VERSION ""

NS_ :

BS_:

BU_: microSDM_102 PDM30 MS6 IM_GCM IZZE_RL IZZE_FL IZZE_RR IZZE_FR IMU WL_IZZE_RIGHT WL_IZZE_LEFT IZZE_BRK_IR IM_PDM IM_Wheel S350

BO_ 3221225472 VECTOR__INDEPENDENT_SIG_MSG: 0 Vector__XXX
 SG_ LT2_Lambda_2 : 0|16@1+ (0.001,0) [0|0] "L" Vector__XXX
 SG_ LT2_Row_Count : 0|8@1+ (1,0) [0|0] "" Vector__XXX
 SG_ LT2_Lambda_1 : 0|16@1+ (0.001,0) [0|0] "L" Vector__XXX
 SG_ LT2_Row_Count : 0|8@1+ (1,0) [0|0] "" Vector__XXX
 SG_ LT2_Lambda_2 : 0|16@1+ (0.001,0) [0|0] "L" Vector__XXX
 SG_ LT2_Row_Count : 0|8@1+ (1,0) [0|0] "" Vector__XXX
 SG_ LT2_Lambda_1 : 0|16@1+ (0.001,0) [0|0] "L" Vector__XXX
 SG_ LT2_Row_Count : 0|8@1+ (1,0) [0|0] "" Vector__XXX

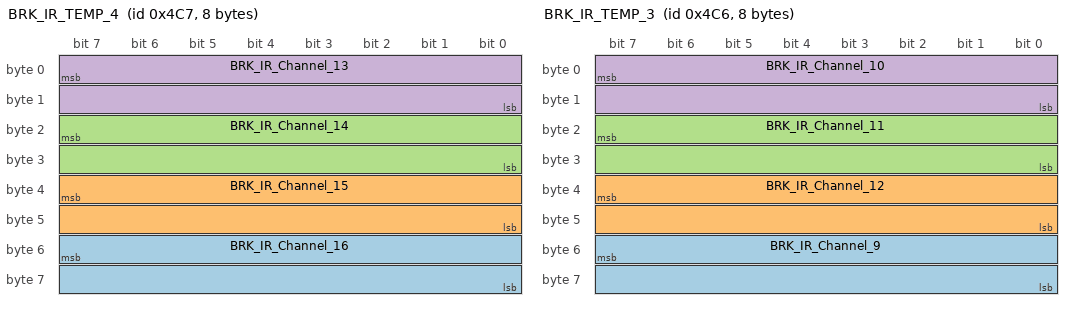
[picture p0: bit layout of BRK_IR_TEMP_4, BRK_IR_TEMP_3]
BO_ 1223 BRK_IR_TEMP_4: 8 IZZE_BRK_IR
 SG_ BRK_IR_Channel_16 : 55|16@0+ (0.1,-100) [0|65535] "C" Vector__XXX
 SG_ BRK_IR_Channel_15 : 39|16@0+ (0.1,-100) [0|65535] "C" Vector__XXX
 SG_ BRK_IR_Channel_14 : 23|16@0+ (0.1,-100) [0|65535] "C" Vector__XXX
 SG_ BRK_IR_Channel_13 : 7|16@0+ (0.1,-100) [0|65535] "C" Vector__XXX

BO_ 1222 BRK_IR_TEMP_3: 8 IZZE_BRK_IR
 SG_ BRK_IR_Channel_9 : 55|16@0+ (0.1,-100) [0|65535] "C" Vector__XXX
 SG_ BRK_IR_Channel_12 : 39|16@0+ (0.1,-100) [0|65535] "C" Vector__XXX
 SG_ BRK_IR_Channel_11 : 23|16@0+ (0.1,-100) [0|65535] "C" Vector__XXX
 SG_ BRK_IR_Channel_10 : 7|16@0+ (0.1,-100) [0|65535] "C" Vector__XXX

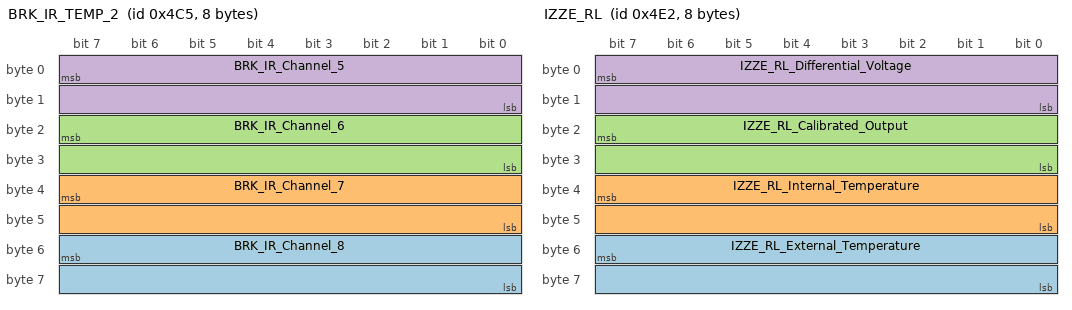
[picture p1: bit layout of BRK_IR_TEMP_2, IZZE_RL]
BO_ 1221 BRK_IR_TEMP_2: 8 IZZE_BRK_IR
 SG_ BRK_IR_Channel_8 : 55|16@0+ (0.1,-100) [0|65535] "C" Vector__XXX
 SG_ BRK_IR_Channel_7 : 39|16@0+ (0.1,-100) [0|65535] "C" Vector__XXX
 SG_ BRK_IR_Channel_6 : 23|16@0+ (0.1,-100) [0|65535] "C" Vector__XXX
 SG_ BRK_IR_Channel_5 : 7|16@0+ (0.1,-100) [0|65535] "C" Vector__XXX

BO_ 1552 IM_GCM_MS6_Control: 8 IM_GCM
 SG_ GCM_Upshift_Bosch : 1|1@1+ (1,0) [0|0] "" Vector__XXX
 SG_ GCM_Downshift_Bosch : 0|1@1+ (1,0) [0|0] "" Vector__XXX

BO_ 1250 IZZE_RL: 8 IZZE_RL
 SG_ IZZE_RL_External_Temperature : 55|16@0- (0.1,0) [0|0] "C" Vector__XXX
 SG_ IZZE_RL_Internal_Temperature : 39|16@0- (0.1,0) [0|0] "C" Vector__XXX
 SG_ IZZE_RL_Calibrated_Output : 23|16@0- (0.1,0) [0|0] "F" Vector__XXX
 SG_ IZZE_RL_Differential_Voltage : 7|16@0- (1,0) [0|0] "µV" Vector__XXX

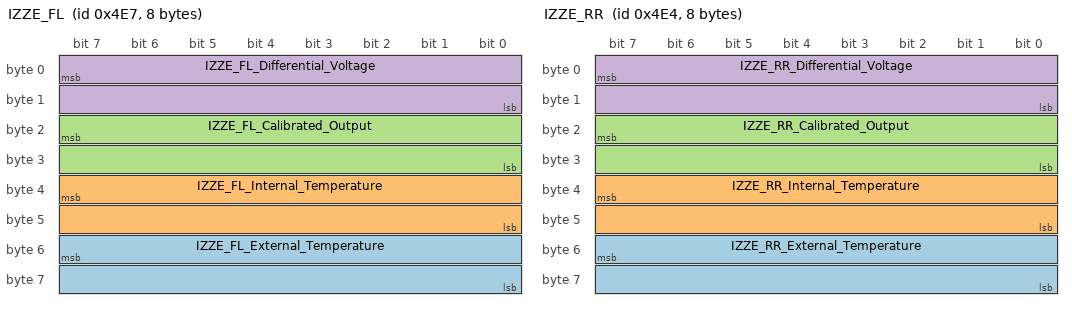
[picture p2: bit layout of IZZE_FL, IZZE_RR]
BO_ 1255 IZZE_FL: 8 IZZE_FL
 SG_ IZZE_FL_External_Temperature : 55|16@0- (0.1,0) [0|0] "C" Vector__XXX
 SG_ IZZE_FL_Internal_Temperature : 39|16@0- (0.1,0) [0|0] "C" Vector__XXX
 SG_ IZZE_FL_Calibrated_Output : 23|16@0- (0.1,0) [0|0] "F" Vector__XXX
 SG_ IZZE_FL_Differential_Voltage : 7|16@0- (1,0) [0|0] "µV" Vector__XXX

BO_ 1252 IZZE_RR: 8 IZZE_RR
 SG_ IZZE_RR_External_Temperature : 55|16@0- (0.1,0) [0|0] "C" Vector__XXX
 SG_ IZZE_RR_Internal_Temperature : 39|16@0- (0.1,0) [0|0] "C" Vector__XXX
 SG_ IZZE_RR_Calibrated_Output : 23|16@0- (0.1,0) [0|0] "F" Vector__XXX
 SG_ IZZE_RR_Differential_Voltage : 7|16@0- (1,0) [0|0] "µV" Vector__XXX

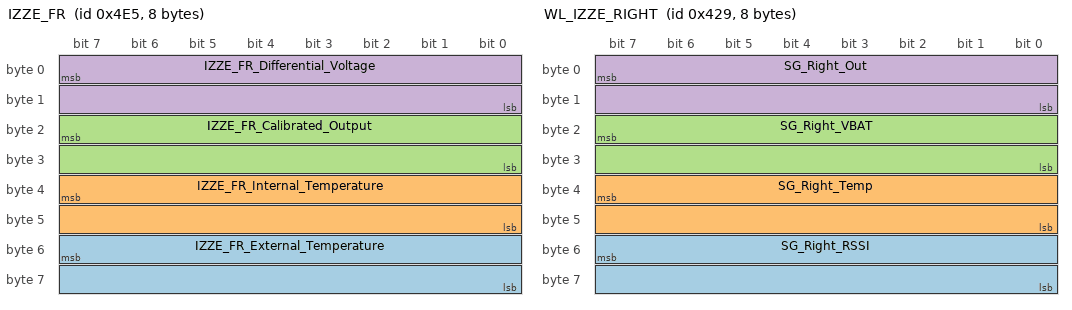
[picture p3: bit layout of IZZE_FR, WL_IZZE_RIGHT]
BO_ 1253 IZZE_FR: 8 IZZE_FR
 SG_ IZZE_FR_External_Temperature : 55|16@0- (0.1,0) [0|0] "C" Vector__XXX
 SG_ IZZE_FR_Internal_Temperature : 39|16@0- (0.1,0) [0|0] "C" Vector__XXX
 SG_ IZZE_FR_Calibrated_Output : 23|16@0- (0.1,0) [0|0] "F" Vector__XXX
 SG_ IZZE_FR_Differential_Voltage : 7|16@0- (1,0) [0|0] "µV" Vector__XXX

BO_ 380 IMU_2: 8 IMU
 SG_ IMU_Z_Accel : 32|16@1+ (0.0001274,-4.1746432) [0|0] "g" Vector__XXX

BO_ 1065 WL_IZZE_RIGHT: 8 WL_IZZE_RIGHT
 SG_ SG_Right_RSSI : 55|16@0- (1,0) [0|0] "dBm" Vector__XXX
 SG_ SG_Right_Temp : 39|16@0- (0.1,0) [0|0] "C" Vector__XXX
 SG_ SG_Right_VBAT : 23|16@0- (0.001,0) [0|0] "V" Vector__XXX
 SG_ SG_Right_Out : 7|16@0- (-1,0) [0|0] "uV" Vector__XXX

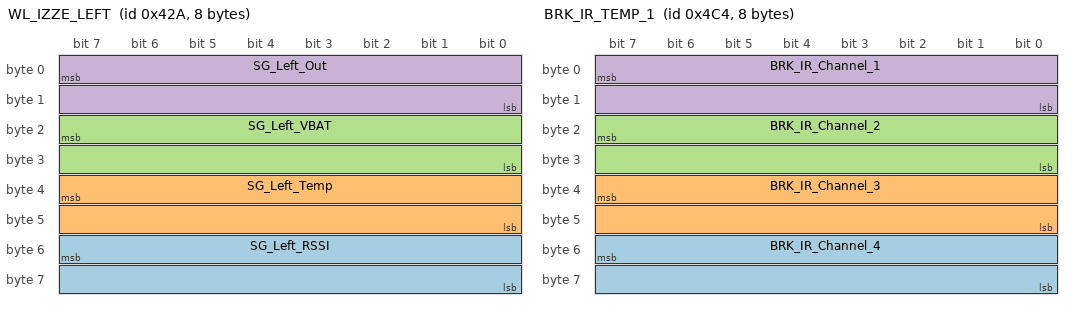
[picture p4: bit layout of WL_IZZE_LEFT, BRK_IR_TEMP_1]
BO_ 1066 WL_IZZE_LEFT: 8 WL_IZZE_LEFT
 SG_ SG_Left_RSSI : 55|16@0- (1,0) [0|0] "dBm" Vector__XXX
 SG_ SG_Left_Temp : 39|16@0- (0.1,0) [0|0] "C" Vector__XXX
 SG_ SG_Left_VBAT : 23|16@0- (0.001,0) [0|0] "V" Vector__XXX
 SG_ SG_Left_Out : 7|16@0- (1,0) [0|0] "uV" Vector__XXX

BO_ 1220 BRK_IR_TEMP_1: 8 IZZE_BRK_IR
 SG_ BRK_IR_Channel_4 : 55|16@0+ (0.1,-100) [0|65535] "C" Vector__XXX
 SG_ BRK_IR_Channel_3 : 39|16@0+ (0.1,-100) [0|65535] "C" Vector__XXX
 SG_ BRK_IR_Channel_2 : 23|16@0+ (0.1,-100) [0|65535] "C" Vector__XXX
 SG_ BRK_IR_Channel_1 : 7|16@0+ (0.1,-100) [0|65535] "C" Vector__XXX

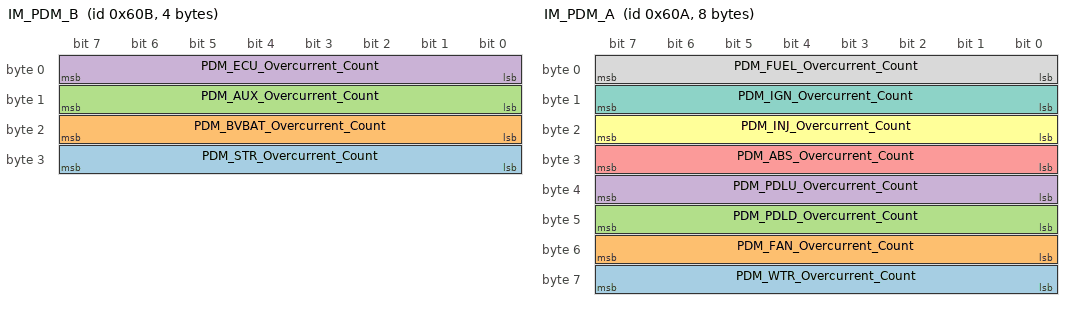
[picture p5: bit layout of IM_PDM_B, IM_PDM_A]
BO_ 1547 IM_PDM_B: 4 IM_PDM
 SG_ PDM_STR_Overcurrent_Count : 24|8@1+ (1,0) [0|0] "" Vector__XXX
 SG_ PDM_BVBAT_Overcurrent_Count : 16|8@1+ (1,0) [0|0] "" Vector__XXX
 SG_ PDM_AUX_Overcurrent_Count : 8|8@1+ (1,0) [0|0] "" Vector__XXX
 SG_ PDM_ECU_Overcurrent_Count : 0|8@1+ (1,0) [0|0] "" Vector__XXX

BO_ 1546 IM_PDM_A: 8 IM_PDM
 SG_ PDM_WTR_Overcurrent_Count : 56|8@1+ (1,0) [0|0] "" Vector__XXX
 SG_ PDM_FAN_Overcurrent_Count : 48|8@1+ (1,0) [0|0] "" Vector__XXX
 SG_ PDM_PDLD_Overcurrent_Count : 40|8@1+ (1,0) [0|0] "" Vector__XXX
 SG_ PDM_PDLU_Overcurrent_Count : 32|8@1+ (1,0) [0|0] "" Vector__XXX
 SG_ PDM_ABS_Overcurrent_Count : 24|8@1+ (1,0) [0|0] "" Vector__XXX
 SG_ PDM_INJ_Overcurrent_Count : 16|8@1+ (1,0) [0|0] "" Vector__XXX
 SG_ PDM_IGN_Overcurrent_Count : 8|8@1+ (1,0) [0|0] "" Vector__XXX
 SG_ PDM_FUEL_Overcurrent_Count : 0|8@1+ (1,0) [0|0] "" Vector__XXX

BO_ 376 IMU_1: 8 IMU
 SG_ IMU_X_Accel : 32|16@1+ (0.0001274,-4.1746432) [0|0] "g" Vector__XXX
 SG_ IMU_Roll_Rate : 0|16@1+ (0.005,-163.84) [0|0] "deg/s/s" Vector__XXX

BO_ 372 IMU_0: 8 IMU
 SG_ IMU_Y_Accel : 32|16@1+ (0.0001274,-4.1746432) [0|0] "g" Vector__XXX
 SG_ IMU_Yaw_Rate : 0|16@1+ (0.005,-163.84) [0|0] "deg/s" Vector__XXX

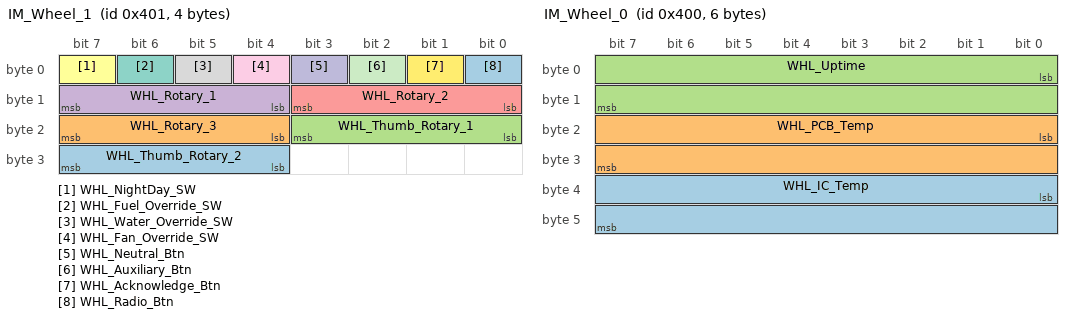
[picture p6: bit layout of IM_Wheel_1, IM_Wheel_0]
BO_ 1025 IM_Wheel_1: 4 IM_Wheel
 SG_ WHL_Thumb_Rotary_2 : 28|4@1+ (1,0) [0|0] "" Vector__XXX
 SG_ WHL_Rotary_3 : 20|4@1+ (1,0) [0|0] "" Vector__XXX
 SG_ WHL_Thumb_Rotary_1 : 16|4@1+ (1,0) [0|0] "" Vector__XXX
 SG_ WHL_Rotary_1 : 12|4@1+ (1,0) [0|0] "" Vector__XXX
 SG_ WHL_Rotary_2 : 8|4@1+ (1,0) [0|0] "" Vector__XXX
 SG_ WHL_NightDay_SW : 7|1@1+ (1,0) [0|0] "" Vector__XXX
 SG_ WHL_Fuel_Override_SW : 6|1@1+ (1,0) [0|0] "" Vector__XXX
 SG_ WHL_Water_Override_SW : 5|1@1+ (1,0) [0|0] "" Vector__XXX
 SG_ WHL_Fan_Override_SW : 4|1@1+ (1,0) [0|0] "" Vector__XXX
 SG_ WHL_Neutral_Btn : 3|1@1+ (1,0) [0|0] "" Vector__XXX
 SG_ WHL_Auxiliary_Btn : 2|1@1+ (1,0) [0|0] "" Vector__XXX
 SG_ WHL_Acknowledge_Btn : 1|1@1+ (1,0) [0|0] "" Vector__XXX
 SG_ WHL_Radio_Btn : 0|1@1+ (1,0) [0|0] "" Vector__XXX

BO_ 1024 IM_Wheel_0: 6 IM_Wheel
 SG_ WHL_IC_Temp : 32|16@1- (0.005,0) [0|0] "C" Vector__XXX
 SG_ WHL_PCB_Temp : 16|16@1- (0.005,0) [0|0] "C" Vector__XXX
 SG_ WHL_Uptime : 0|16@1+ (1,0) [0|0] "s" Vector__XXX

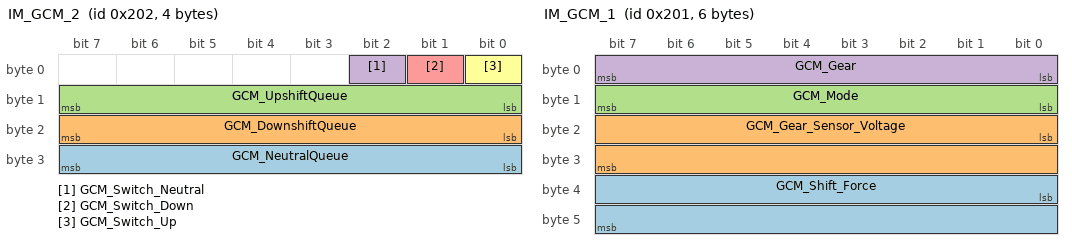
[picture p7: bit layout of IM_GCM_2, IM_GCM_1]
BO_ 514 IM_GCM_2: 4 IM_GCM
 SG_ GCM_NeutralQueue : 24|8@1+ (1,0) [0|0] "" Vector__XXX
 SG_ GCM_DownshiftQueue : 16|8@1+ (1,0) [0|0] "" Vector__XXX
 SG_ GCM_UpshiftQueue : 8|8@1+ (1,0) [0|0] "" Vector__XXX
 SG_ GCM_Switch_Neutral : 2|1@1+ (1,0) [0|0] "" Vector__XXX
 SG_ GCM_Switch_Down : 1|1@1+ (1,0) [0|0] "" Vector__XXX
 SG_ GCM_Switch_Up : 0|1@1+ (1,0) [0|0] "" Vector__XXX

BO_ 513 IM_GCM_1: 6 IM_GCM
 SG_ GCM_Shift_Force : 32|16@1- (0.01,0) [0|0] "N" Vector__XXX
 SG_ GCM_Gear_Sensor_Voltage : 16|16@1+ (0.0001,0) [0|0] "V" Vector__XXX
 SG_ GCM_Mode : 8|8@1+ (1,0) [0|0] "" Vector__XXX
 SG_ GCM_Gear : 0|8@1+ (1,0) [0|0] "" Vector__XXX

BO_ 15 IM_ERR: 4 IM_Wheel
 SG_ ERR_Code : 16|16@1+ (1,0) [0|0] "" Vector__XXX
 SG_ ERR_Origin_Node : 0|16@1+ (1,0) [0|0] "" Vector__XXX

BO_ 1537 IM_PDM_1: 8 IM_PDM
 SG_ PDM_FuelPrime : 63|1@1+ (1,0) [0|0] "" Vector__XXX
 SG_ PDM_OverTemp : 62|1@1+ (1,0) [0|0] "" Vector__XXX
 SG_ PDM_STR_SW : 55|1@1+ (1,0) [0|0] "" Vector__XXX
 SG_ PDM_ON_SW : 54|1@1+ (1,0) [0|0] "" Vector__XXX
 SG_ PDM_ACT_UP_SW : 53|1@1+ (1,0) [0|0] "" Vector__XXX
 SG_ PDM_ACT_DN_SW : 52|1@1+ (1,0) [0|0] "" Vector__XXX
 SG_ PDM_KILL_SW : 51|1@1+ (1,0) [0|0] "" Vector__XXX
 SG_ PDM_ABS_SW : 50|1@1+ (1,0) [0|0] "" Vector__XXX
 SG_ PDM_AUX1_SW : 49|1@1+ (1,0) [0|0] "" Vector__XXX
 SG_ PDM_AUX2_SW : 48|1@1+ (1,0) [0|0] "" Vector__XXX
 SG_ PDM_Total_Current : 32|16@1+ (0.01,0) [0|0] "A" Vector__XXX
 SG_ PDM_FUEL_Peak : 31|1@1+ (1,0) [0|0] "" Vector__XXX
 SG_ PDM_IGN_Peak : 30|1@1+ (1,0) [0|0] "" Vector__XXX
 SG_ PDM_INJ_Peak : 29|1@1+ (1,0) [0|0] "" Vector__XXX
 SG_ PDM_ABS_Peak : 28|1@1+ (1,0) [0|0] "" Vector__XXX
 SG_ PDM_PDLU_Peak : 27|1@1+ (1,0) [0|0] "" Vector__XXX
 SG_ PDM_PDLD_Peak : 26|1@1+ (1,0) [0|0] "" Vector__XXX
 SG_ PDM_FAN_Peak : 25|1@1+ (1,0) [0|0] "" Vector__XXX
 SG_ PDM_WTR_Peak : 24|1@1+ (1,0) [0|0] "" Vector__XXX
 SG_ PDM_ECU_Peak : 23|1@1+ (1,0) [0|0] "" Vector__XXX
 SG_ PDM_AUX_Peak : 22|1@1+ (1,0) [0|0] "" Vector__XXX
 SG_ PDM_BVBAT_Peak : 21|1@1+ (1,0) [0|0] "" Vector__XXX
 SG_ PDM_STR_Peak : 20|1@1+ (1,0) [0|0] "" Vector__XXX
 SG_ PDM_FUEL_Enabled : 15|1@1+ (1,0) [0|0] "" Vector__XXX
 SG_ PDM_IGN_Enabled : 14|1@1+ (1,0) [0|0] "" Vector__XXX
 SG_ PDM_INJ_Enabled : 13|1@1+ (1,0) [0|0] "" Vector__XXX
 SG_ PDM_ABS_Enabled : 12|1@1+ (1,0) [0|0] "" Vector__XXX
 SG_ PDM_PDLU_Enabled : 11|1@1+ (1,0) [0|0] "" Vector__XXX
 SG_ PDM_PDLD_Enabled : 10|1@1+ (1,0) [0|0] "" Vector__XXX
 SG_ PDM_FAN_Enabled : 9|1@1+ (1,0) [0|0] "" Vector__XXX
 SG_ PDM_WTR_Enabled : 8|1@1+ (1,0) [0|0] "" Vector__XXX
 SG_ PDM_ECU_Enabled : 7|1@1+ (1,0) [0|0] "" Vector__XXX
 SG_ PDM_AUX_Enabled : 6|1@1+ (1,0) [0|0] "" Vector__XXX
 SG_ PDM_BVBAT_Enabled : 5|1@1+ (1,0) [0|0] "" Vector__XXX
 SG_ PDM_STR_Enabled : 4|1@1+ (1,0) [0|0] "" Vector__XXX

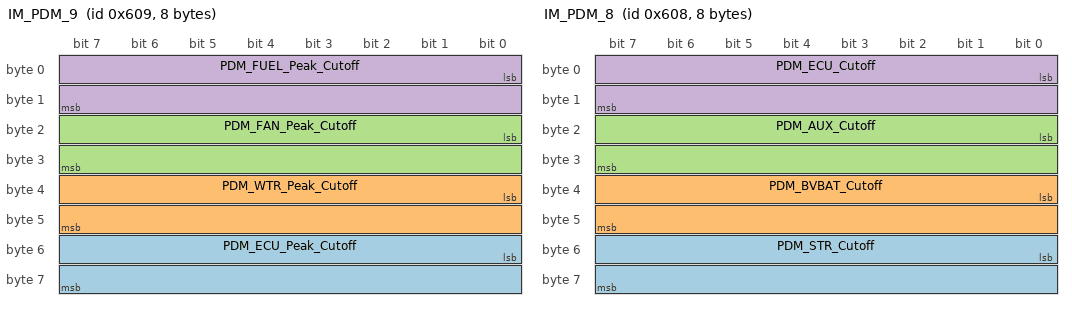
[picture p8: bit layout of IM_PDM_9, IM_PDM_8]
BO_ 1545 IM_PDM_9: 8 IM_PDM
 SG_ PDM_ECU_Peak_Cutoff : 48|16@1+ (0.0025,0) [0|0] "A" Vector__XXX
 SG_ PDM_WTR_Peak_Cutoff : 32|16@1+ (0.0025,0) [0|0] "A" Vector__XXX
 SG_ PDM_FAN_Peak_Cutoff : 16|16@1+ (0.0025,0) [0|0] "A" Vector__XXX
 SG_ PDM_FUEL_Peak_Cutoff : 0|16@1+ (0.0025,0) [0|0] "A" Vector__XXX

BO_ 1544 IM_PDM_8: 8 IM_PDM
 SG_ PDM_STR_Cutoff : 48|16@1+ (0.0025,0) [0|0] "A" Vector__XXX
 SG_ PDM_BVBAT_Cutoff : 32|16@1+ (0.0025,0) [0|0] "A" Vector__XXX
 SG_ PDM_AUX_Cutoff : 16|16@1+ (0.0025,0) [0|0] "A" Vector__XXX
 SG_ PDM_ECU_Cutoff : 0|16@1+ (0.0025,0) [0|0] "A" Vector__XXX

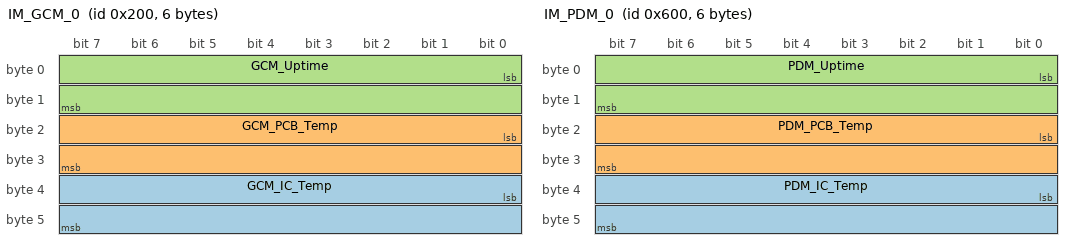
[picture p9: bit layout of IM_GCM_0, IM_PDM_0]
BO_ 512 IM_GCM_0: 6 IM_GCM
 SG_ GCM_IC_Temp : 32|16@1- (0.005,0) [0|0] "C" Vector__XXX
 SG_ GCM_PCB_Temp : 16|16@1- (0.005,0) [0|0] "C" Vector__XXX
 SG_ GCM_Uptime : 0|16@1+ (1,0) [0|0] "s" Vector__XXX

BO_ 1536 IM_PDM_0: 6 IM_PDM
 SG_ PDM_IC_Temp : 32|16@1- (0.005,0) [0|0] "C" Vector__XXX
 SG_ PDM_PCB_Temp : 16|16@1- (0.005,0) [0|0] "C" Vector__XXX
 SG_ PDM_Uptime : 0|16@1+ (1,0) [0|0] "s" Vector__XXX

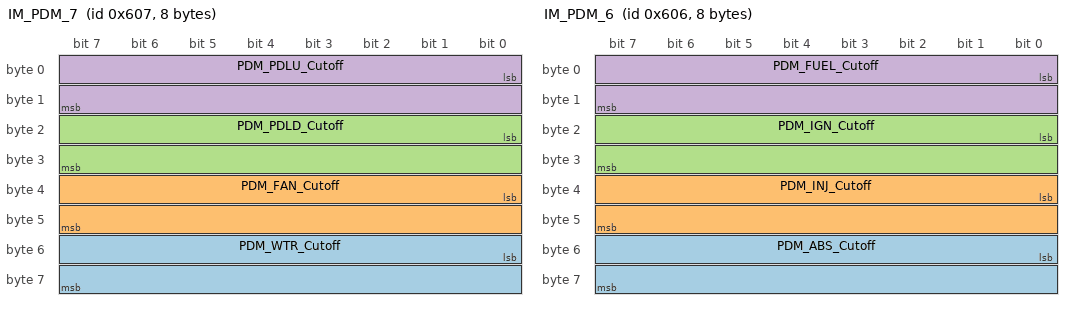
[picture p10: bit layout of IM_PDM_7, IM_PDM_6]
BO_ 1543 IM_PDM_7: 8 IM_PDM
 SG_ PDM_WTR_Cutoff : 48|16@1+ (0.0025,0) [0|0] "A" Vector__XXX
 SG_ PDM_FAN_Cutoff : 32|16@1+ (0.0025,0) [0|0] "A" Vector__XXX
 SG_ PDM_PDLD_Cutoff : 16|16@1+ (0.0025,0) [0|0] "A" Vector__XXX
 SG_ PDM_PDLU_Cutoff : 0|16@1+ (0.0025,0) [0|0] "A" Vector__XXX

BO_ 1542 IM_PDM_6: 8 IM_PDM
 SG_ PDM_ABS_Cutoff : 48|16@1+ (0.0025,0) [0|0] "A" Vector__XXX
 SG_ PDM_INJ_Cutoff : 32|16@1+ (0.0025,0) [0|0] "A" Vector__XXX
 SG_ PDM_IGN_Cutoff : 16|16@1+ (0.0025,0) [0|0] "A" Vector__XXX
 SG_ PDM_FUEL_Cutoff : 0|16@1+ (0.0025,0) [0|0] "A" Vector__XXX

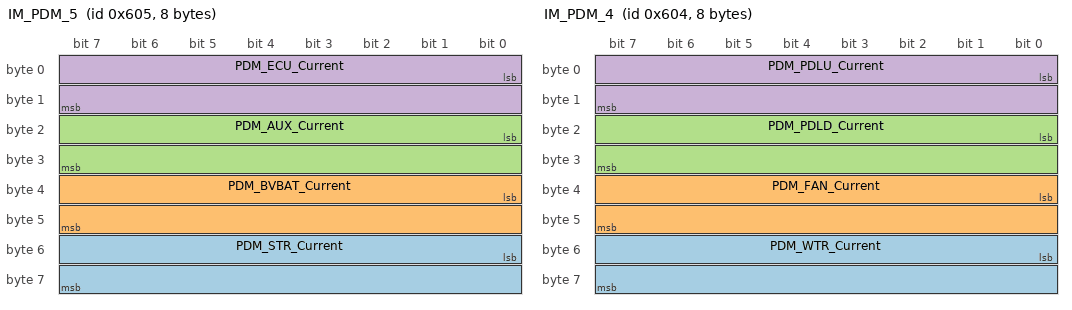
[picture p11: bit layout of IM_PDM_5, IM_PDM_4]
BO_ 1541 IM_PDM_5: 8 IM_PDM
 SG_ PDM_STR_Current : 48|16@1+ (0.01,0) [0|0] "A" Vector__XXX
 SG_ PDM_BVBAT_Current : 32|16@1+ (0.001,0) [0|0] "A" Vector__XXX
 SG_ PDM_AUX_Current : 16|16@1+ (0.001,0) [0|0] "A" Vector__XXX
 SG_ PDM_ECU_Current : 0|16@1+ (0.001,0) [0|0] "A" Vector__XXX

BO_ 1540 IM_PDM_4: 8 IM_PDM
 SG_ PDM_WTR_Current : 48|16@1+ (0.001,0) [0|0] "A" Vector__XXX
 SG_ PDM_FAN_Current : 32|16@1+ (0.001,0) [0|0] "A" Vector__XXX
 SG_ PDM_PDLD_Current : 16|16@1+ (0.001,0) [0|0] "A" Vector__XXX
 SG_ PDM_PDLU_Current : 0|16@1+ (0.001,0) [0|0] "A" Vector__XXX

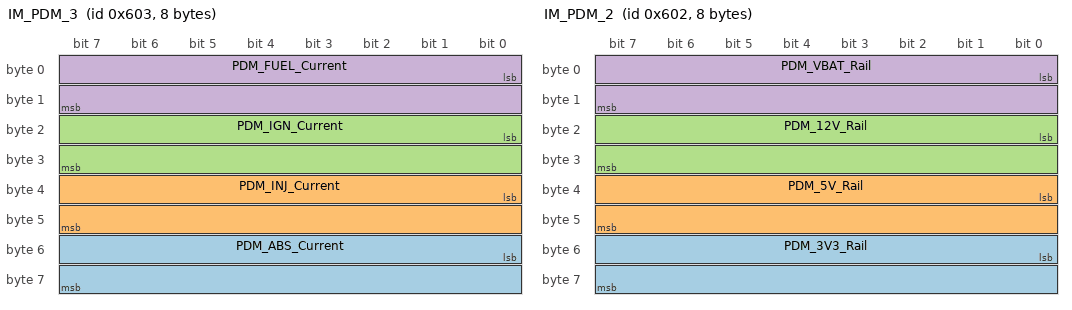
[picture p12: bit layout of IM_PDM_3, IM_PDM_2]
BO_ 1539 IM_PDM_3: 8 IM_PDM
 SG_ PDM_ABS_Current : 48|16@1+ (0.001,0) [0|0] "A" Vector__XXX
 SG_ PDM_INJ_Current : 32|16@1+ (0.001,0) [0|0] "A" Vector__XXX
 SG_ PDM_IGN_Current : 16|16@1+ (0.001,0) [0|0] "A" Vector__XXX
 SG_ PDM_FUEL_Current : 0|16@1+ (0.001,0) [0|0] "A" Vector__XXX

BO_ 1538 IM_PDM_2: 8 IM_PDM
 SG_ PDM_3V3_Rail : 48|16@1+ (0.001,0) [0|0] "V" Vector__XXX
 SG_ PDM_5V_Rail : 32|16@1+ (0.001,0) [0|0] "V" Vector__XXX
 SG_ PDM_12V_Rail : 16|16@1+ (0.001,0) [0|0] "V" Vector__XXX
 SG_ PDM_VBAT_Rail : 0|16@1+ (0.001,0) [0|0] "V" Vector__XXX

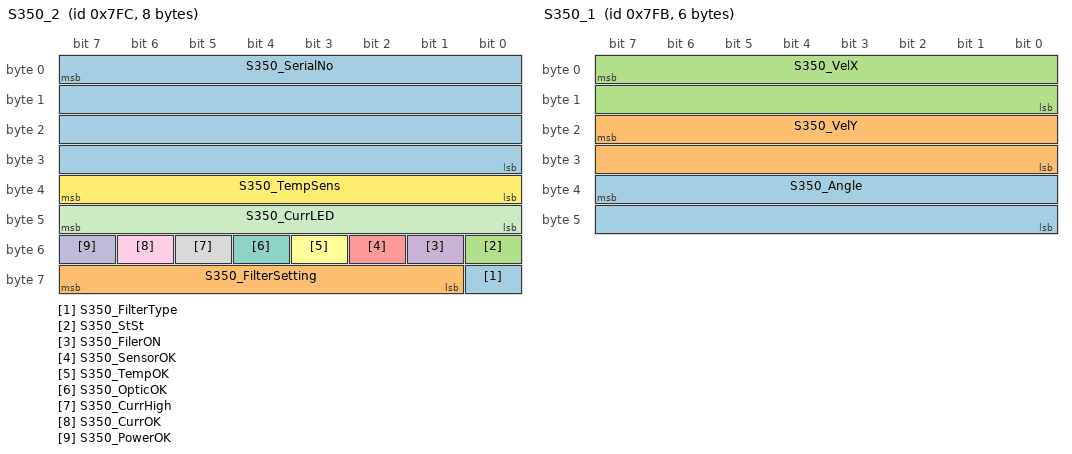
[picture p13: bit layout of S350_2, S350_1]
BO_ 2044 S350_2: 8 S350
 SG_ S350_FilterType : 56|1@0+ (1,0) [0|1] ""  S350
 SG_ S350_FilterSetting : 63|7@0+ (1,0) [0|127] ""  S350
 SG_ S350_StSt : 48|1@0+ (1,0) [0|1] ""  S350
 SG_ S350_FilerON : 49|1@0+ (1,0) [0|1] ""  S350
 SG_ S350_SensorOK : 50|1@0+ (1,0) [0|1] ""  S350
 SG_ S350_TempOK : 51|1@0+ (1,0) [0|1] ""  S350
 SG_ S350_OpticOK : 52|1@0+ (1,0) [0|1] ""  S350
 SG_ S350_CurrHigh : 53|1@0+ (1,0) [0|1] ""  S350
 SG_ S350_CurrOK : 54|1@0+ (1,0) [0|1] ""  S350
 SG_ S350_PowerOK : 55|1@0+ (1,0) [0|1] ""  S350
 SG_ S350_CurrLED : 47|8@0+ (0.01,0) [0|2.55] "A"  S350
 SG_ S350_TempSens : 39|8@0- (1,0) [-128|127] "°C"  S350
 SG_ S350_SerialNo : 7|32@0+ (1,0) [0|4294970000] ""  S350

BO_ 2043 S350_1: 6 S350
 SG_ S350_Angle : 39|16@0- (0.01,0) [-45|45] "°"  S350
 SG_ S350_VelY : 23|16@0- (0.036,0) [-100|100] "km/h"  S350
 SG_ S350_VelX : 7|16@0+ (0.036,0) [0|400] "km/h"  S350

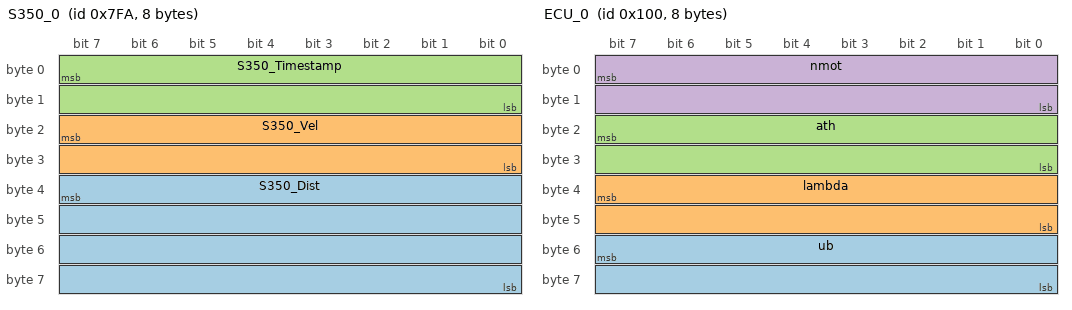
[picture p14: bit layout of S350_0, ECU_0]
BO_ 2042 S350_0: 8 S350
 SG_ S350_Dist : 39|32@0+ (0.001,0) [0|4294970] "m"  S350
 SG_ S350_Vel : 23|16@0+ (0.036,0) [0|400] "km/h"  S350
 SG_ S350_Timestamp : 7|16@0+ (1,0) [0|65535] ""  S350

BO_ 256 ECU_0: 8 MS6
 SG_ ub : 55|16@0- (0.01,0) [0|25.5] "V" Vector__XXX
 SG_ lambda : 39|16@0- (0.001,0) [0|5] "" Vector__XXX
 SG_ ath : 23|16@0- (0.1,0) [0|110] "%" Vector__XXX
 SG_ nmot : 7|16@0- (1,0) [0|20000] "rpm" Vector__XXX

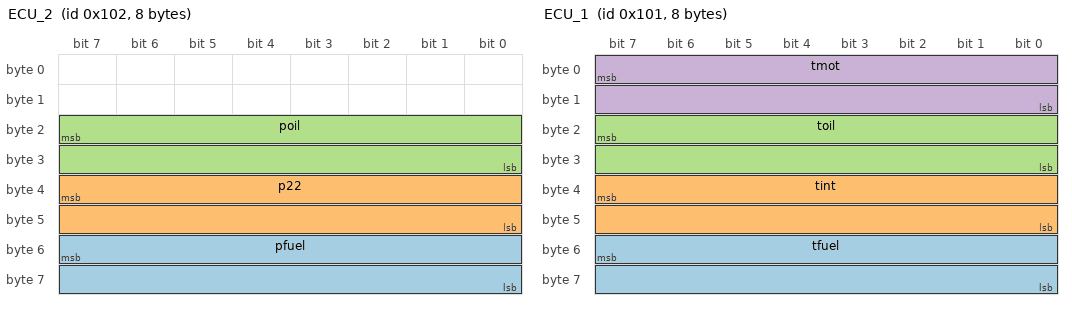
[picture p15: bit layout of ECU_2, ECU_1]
BO_ 258 ECU_2: 8 MS6
 SG_ pfuel : 55|16@0- (0.001,0) [0|10] "bar" Vector__XXX
 SG_ p22 : 39|16@0- (1,0) [0|5000] "mbar" Vector__XXX
 SG_ poil : 23|16@0- (0.001,0) [0|10] "bar" Vector__XXX

BO_ 257 ECU_1: 8 MS6
 SG_ tfuel : 55|16@0+ (0.1,0) [10|80] "°C" Vector__XXX
 SG_ tint : 39|16@0- (0.1,0) [10|60] "°C" Vector__XXX
 SG_ toil : 23|16@0- (0.1,0) [60|150] "°C" Vector__XXX
 SG_ tmot : 7|16@0- (0.1,0) [40|120] "°C" Vector__XXX

BO_ 259 ECU_3: 8 MS6

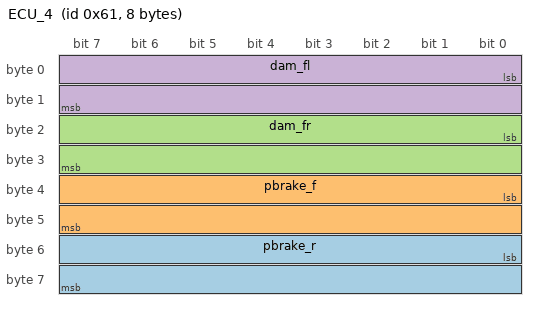
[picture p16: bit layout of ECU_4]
BO_ 97 ECU_4: 8 MS6
 SG_ pbrake_r : 48|16@1+ (0.005,0) [0|150] "bar" Vector__XXX
 SG_ pbrake_f : 32|16@1+ (0.005,0) [0|150] "bar" Vector__XXX
 SG_ dam_fr : 16|16@1+ (0.015,0) [-400|400] "mm" Vector__XXX
 SG_ dam_fl : 0|16@1+ (0.015,0) [-400|400] "mm" Vector__XXX

BO_TX_BU_ 15 : IM_GCM,IM_PDM,IM_Wheel;

CM_ BU_ microSDM_102 "Plex microSDM 102 Pro Display Unit (Wheel)";
CM_ BU_ PDM30 "MoTeC PDM30 Power Distribution Module";
CM_ BU_ MS6 "Bosch Motorsport MS6.2 ECU";
CM_ BU_ IM_GCM "Illini Motorsports Gear Control Module";
CM_ BU_ IZZE_RL "IZZE Strain Gauge - Rear Left";
CM_ BU_ IZZE_FL "IZZE Strain Gauge - Front Left";
CM_ BU_ IZZE_RR "IZZE Strain Gauge - Rear Right";
CM_ BU_ IZZE_FR "IZZE Strain Gauge - Front Right";
CM_ BU_ IMU "Bosch IMU";
CM_ BU_ WL_IZZE_RIGHT "Wireless IZZE Strain Gauge - Right Drive Shaft";
CM_ BU_ WL_IZZE_LEFT "Wireless IZZE Strain Gauge - Left Drive Shaft";
CM_ BU_ IZZE_BRK_IR "IZZE Brake IR Temperature Sensor";
CM_ BU_ IM_PDM "Illini Motorsports Power Distribution Model";
CM_ BU_ IM_Wheel "Illini Motorsports Wheel";
CM_ BU_ S350 "Kistler S350 Slip Angle Sensor";
CM_ BO_ 3221225472 "This is a message for not used signals, created by Vector CANdb++ DBC OLE DB Provider.";
CM_ BO_ 1223 "Brake IR channels 13-16";
CM_ BO_ 1222 "Brake IR channels 9-12";
CM_ BO_ 1221 "Brake IR channels 5-8";
CM_ BO_ 1552 "Upshift/downshift ignition cut triggers for the MS6";
CM_ BO_ 1250 "Rear left IZZE - raw voltage, calibrated output, temperatures";
CM_ BO_ 1255 "Front left IZZE - raw voltage, calibrated output, temperatures";
CM_ BO_ 1252 "Rear right IZZE - raw voltage, calibrated output, temperatures";
CM_ BO_ 1253 "Front right IZZE - raw voltage, calibrated output, temperatures";
CM_ BO_ 380 "Z accel";
CM_ BO_ 1065 "Right wireless IZZE - Output, Battery, Temperature, RSSI";
CM_ BO_ 1066 "Left wireless IZZE - Output, Battery, Temperature, RSSI";
CM_ BO_ 1220 "Brake IR channels 1-4";
CM_ BO_ 1547 "Overcurrent counts 2";
CM_ BO_ 1546 "Overcurrent counts";
CM_ BO_ 376 "Roll rate, X accel";
CM_ BO_ 372 "Yaw rate, Y accel";
CM_ BO_ 1025 "Input values";
CM_ BO_ 1024 "Uptime, Temperatures";
CM_ BO_ 514 "Paddles, Shift Queues";
CM_ BO_ 513 "Gear, Gear Sensor Voltage, Mode, Shift force";
CM_ BO_ 15 "Error flags for IM boards";
CM_ BO_ 1537 "Load enabled statuses, Load peak currents, Total current, Switchbox inputs, Over temperature, Prime ";
CM_ BO_ 1545 "Fuel peak cutoff, Fan peak cutoff, Water peak cutoff, ECU cutoff";
CM_ BO_ 1544 "ECU cutoff, Auxilary cutoff, Backup cutoff, Starter cutoff";
CM_ BO_ 512 "Uptime, Temperatures";
CM_ BO_ 1536 "Uptime, Temperatures";
CM_ BO_ 1543 "Actuator cutoff, Fan cutoff, Water cutoff";
CM_ BO_ 1542 "Fuel cutoff, Ignition cutoff, Injection cutoff, ABS cutoff";
CM_ BO_ 1541 "ECU current, Auxilary current, Backup current, Starter current";
CM_ BO_ 1540 "Actuator current, Fan current, Water pump current";
CM_ BO_ 1539 "Fuel Current, Ignition Current, Injection Current, ABS Current";
CM_ BO_ 1538 "Power rails";
CM_ BO_ 2044 "Device status";
CM_ BO_ 2043 "Velocity X, Velocity Y, Slip angle";
CM_ BO_ 2042 "Timestamp, velocity, distance";
CM_ BO_ 256 "RPM, Throttle Position, Lambda, VBAT";
CM_ SG_ 256 ub "battery voltage";
CM_ SG_ 256 lambda "Lambda actual value";
CM_ SG_ 256 ath "throttle position";
CM_ SG_ 256 nmot "engine speed";
CM_ BO_ 258 "Ambient Pressure, Oil Pressure, Manifold Pressure, Fuel Pressure";
CM_ SG_ 258 pfuel "fuel pressure";
CM_ SG_ 258 p22 "intake manifold pressure downstream throttle";
CM_ SG_ 258 poil "oil pressure";
CM_ BO_ 257 "Coolant Temp, Oil Temp, Manifold Temp, Fuel Temp";
CM_ SG_ 257 tfuel "fuel temperature";
CM_ SG_ 257 tint "intake air temperature";
CM_ SG_ 257 toil "oil temperature";
CM_ SG_ 257 tmot "engine temperature";
CM_ BO_ 259 "Wheel Speeds";
CM_ BO_ 97 "Front Damper Positions, Front Brake Pressure, Rear Brake Pressure";
CM_ SG_ 97 pbrake_r "brake pressure rear";
CM_ SG_ 97 pbrake_f "brake pressure front ";
CM_ SG_ 97 dam_fr "damper position front right";
CM_ SG_ 97 dam_fl "damper position front left";
VAL_ 2044 S350_FilterType 1 "FIR" 0 "MAVG" ;
VAL_ 2044 S350_FilerON 1 "ON" 0 "OFF" ;
